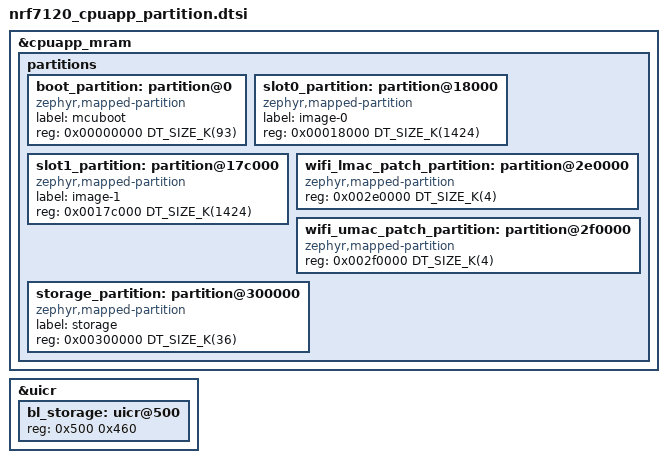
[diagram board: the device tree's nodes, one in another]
/*
 * Copyright (c) 2025 Nordic Semiconductor ASA
 *
 * SPDX-License-Identifier: Apache-2.0
 *
 * Default memory partitioning for nRF7120 application CPU.
 */

/* These partition sizes assume no FLPR area in MRAM */
&cpuapp_mram {
	partitions {
		#address-cells = <1>;
		#size-cells = <1>;
		ranges;

		boot_partition: partition@0 {
			compatible = "zephyr,mapped-partition";
			label = "mcuboot";
			/* MCUBoot partition is set to 93k to allow FPROTECT
			 * to be enabled by default.
			 */
			reg = <0x00000000 DT_SIZE_K(93)>;
		};

		slot0_partition: partition@18000 {
			compatible = "zephyr,mapped-partition";
			label = "image-0";
			reg = <0x00018000 DT_SIZE_K(1424)>;
		};

		slot1_partition: partition@17c000 {
			compatible = "zephyr,mapped-partition";
			label = "image-1";
			reg = <0x0017c000 DT_SIZE_K(1424)>;
		};

		/*
		 * Reserved for Wi-Fi LMAC ROM patch.
		 * Temporary FPGA/bring-up placement.
		 */
		wifi_lmac_patch_partition: partition@2e0000 {
			compatible = "zephyr,mapped-partition";
			reg = <0x002e0000 DT_SIZE_K(4)>;
		};

		/*
		 * Reserved for Wi-Fi UMAC ROM patch.
		 * Temporary FPGA/bring-up placement.
		 */
		wifi_umac_patch_partition: partition@2f0000 {
			compatible = "zephyr,mapped-partition";
			reg = <0x002f0000 DT_SIZE_K(4)>;
		};

		storage_partition: partition@300000 {
			compatible = "zephyr,mapped-partition";
			label = "storage";
			reg = <0x00300000 DT_SIZE_K(36)>;
		};
	};
};

&uicr {
	bl_storage: uicr@500 {
		reg = <0x500 0x460>;
	};
};
